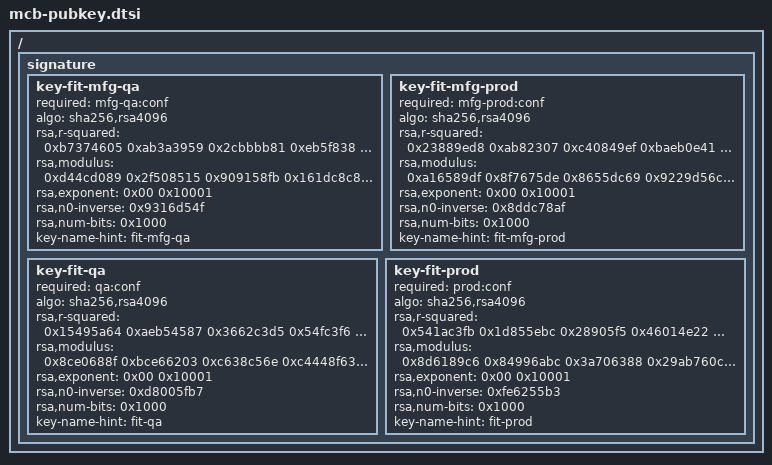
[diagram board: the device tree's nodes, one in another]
/*
 * This is a Device Tree representation of the public keys that will
 * be used for FIT image verification.
 *
 * The procedure to generate this file from production keys in AWS CloudHSM is
 * avaliable here:
 * https://github.com/ChargePoint/emb-platform/blob/master/os/buildroot/package/emb-sbsigner/README.md
 */

/ {
	signature {

		key-fit-mfg-qa {
			required = "mfg-qa:conf";
			algo = "sha256,rsa4096";
			rsa,r-squared = < 0xb7374605 0xab3a3959 0x2cbbbb81 0xeb5f838 0x4bb5653e 0x18479cb6 0x23d0299f 0x4a56102b 0x6a9e6eba 0xea80ffea 0x2d5070d3 0x5fa6fe54 0x507ae7ad 0x3aa41cde 0x8d3a9ec5 0x6e343eb9 0x74f7d490 0xa2283000 0xf7cd028e 0xb794887d 0xb8b51228 0x1b12023f 0xc6bfa648 0x9c294dad 0xa33be023 0xcb2aaed3 0x1f97247 0x3438b15e 0x2d983a2c 0x526e42d4 0x14bdcc2c 0x8b406381 0x181fa997 0xc7b0e240 0x1bff5a28 0xa4deac87 0xe7b06f11 0x18ae0268 0x1ac54201 0xb32e41c5 0xcaaf0143 0x4a75bc9d 0xee715a30 0xf1fad5bf 0xf6d3fed2 0xff18a269 0xe4a86270 0x73f8cc03 0x4ee7aa5b 0x70a17104 0x7c1811c4 0xee1278aa 0xa22c16a2 0x71caebb 0x80285c83 0x7ce4504e 0xffccbbb3 0xe9a33e58 0xc27dc984 0x77eb382e 0x5c9610b7 0xf753acd 0x139deb12 0x29228785 0x30664657 0x906d7fe7 0x4f19ae47 0x1ca5cc12 0x1e208295 0x3cbcb9e2 0x86f11f98 0xe92e1594 0x96698255 0x2dac40fb 0x45a97135 0xe507ae94 0xe5ec1da7 0xeec2c49e 0x47b8ca65 0xe560ae12 0xe63d7650 0x6ab8a9ba 0x5ea440ea 0x78b3335a 0xa39d192 0x9a9b6327 0x4a6e2e52 0x795c4ce6 0x4fa55ec0 0x2efc6b5 0xea68e5df 0x72b4c17e 0x83c40126 0xf93f7625 0xcbe4b2d0 0x5a214246 0x247450e0 0x138197f 0xeee2b322 0x7202af22 0xb77ba753 0x89540957 0x70e0ddce 0xfe02437e 0x11fc7334 0x22f77f8f 0x6d27c05a 0x4e550443 0x1a2a149 0x2f821663 0x2af2fe25 0x1b2d7264 0x1fe17305 0x4994d1d1 0x62718b90 0x417c20e9 0x78d5d38 0xb53ed94b 0x2ba941a5 0x2c01126f 0x75b04cd2 0x4f067000 0x5a27da80 0xd6bb6afa 0x5bad1089 0x26c62004 0xce938f8c 0x9a3a44d >;
			rsa,modulus = < 0xd44cd089 0x2f508515 0x909158fb 0x161dc8c8 0xe42be8e1 0xcb358437 0x4e59c9f3 0xf8543b68 0xc46063a9 0x6f4085a0 0x5c45fb 0x5e05d982 0x8d24a2e 0x9d522364 0x4a76566c 0xd574c659 0xd990678d 0xcb94a136 0x37066b65 0xb46c07b8 0xbdbc9a7 0xf831d136 0x66bcb0b7 0x35665019 0x3116a2c0 0x999b0bd7 0x13ee6e22 0xeb82173b 0x9695264b 0x1ac913ea 0xcfa27c0f 0x995e0480 0x9ed6e5de 0x1e25eee1 0xb8ecfdc9 0x2c061949 0x1115d029 0xa053b099 0xeac0dfb1 0x63f5b33a 0xe37b9b6e 0x3e53d994 0x320fa7bb 0xb23a85cf 0xc55e692f 0x35785e7a 0x92707329 0x49c91f20 0x54d40d21 0xe9045889 0x379cb8e0 0x964ab616 0x4aa06508 0x413e7496 0x274c1c37 0xd146603f 0x783b1f7b 0x59f88fbc 0xcb06b705 0x54998bc1 0x21959b1c 0x51fc777f 0x3676f7dd 0xa80ef651 0xa248c11a 0xb2ba3198 0x14d7cd4d 0x3459ba41 0xcf7643e3 0x6b305db1 0xa4e40595 0x435a2b1f 0x4ea42f 0x1bca30b4 0x813f50e7 0xd231b19a 0x1037cb45 0x5b39e4ff 0x6271152 0x6e49a21c 0xc9a2d516 0xabce00a0 0x9ed09986 0x78c48125 0x39a0b13b 0xdf81ea38 0xa93f87ad 0x28a32d76 0x9dc4c79a 0x664f6a02 0x8c14d961 0x22da3e23 0xea7e044a 0xdd5b4fb8 0x227c1c43 0x3c5a99db 0xf2512163 0x11c90ebc 0xee7ac908 0x14a3d1d1 0x5646e484 0x66946c43 0x7d4f9198 0x2c8ed56f 0x64eb80e4 0x661880bf 0xc557e3b 0x95055d31 0xf9f3acba 0x9b426dcb 0xf742efe0 0x14ec5d46 0x6ab85040 0xadedf8f6 0x2cdb9f45 0xe236a2e9 0xe5536366 0xef085fd6 0x639d39b3 0x9a04b42c 0x7037314b 0xbd386ed2 0x34661843 0x9109be89 0x4f5801e6 0x766b4a89 0x55e7901 0xaf74de51 >;
			rsa,exponent = < 0x00 0x10001 >;
			rsa,n0-inverse = < 0x9316d54f >;
			rsa,num-bits = < 0x1000 >;
			key-name-hint = "fit-mfg-qa";
		};

		key-fit-mfg-prod {
			required = "mfg-prod:conf";
			algo = "sha256,rsa4096";
			rsa,r-squared = < 0x23889ed8 0xab82307 0xc40849ef 0xbaeb0e41 0x5dbce411 0x74c7f91e 0x77b7d250 0x2e4b63bc 0x32fe6bfa 0xf70082f 0x407437f2 0x3c21524a 0xc77dce31 0x8b02f80 0x5bf54f03 0x32970f8d 0x406422d7 0x884ed230 0x156e777b 0xdd82352f 0xcb285f9e 0xd79a7adb 0xd1da32df 0x5fa5f627 0xa7da35ba 0x9ac520b 0x6822dafe 0x365d2c6 0xf539c6b2 0x37f26ad2 0x9fc90bb1 0xe3e40369 0x2ed8f887 0xf39e783b 0xf298713c 0x49af365d 0x9a6db052 0x7ff973e1 0x8af9ae8a 0x276f08bd 0xfe29b3e 0x5d5e0729 0x40d96899 0x108e84e7 0xff19b189 0x95e89e67 0x6e1be4a0 0xc99260f3 0x8faedcd2 0xb6ff8db2 0x89cf4abc 0x8daeeec3 0x6c6b8b79 0x5c0ef38a 0xd371fb2c 0xa55f5412 0x5e5313ba 0xdc2a9a44 0xacef10a4 0x7d66655 0xfcb00906 0x711cf3af 0xb07328cd 0xed39b2e5 0x51794016 0x2893d500 0xa44a737f 0x69449642 0x25090b92 0x42ca92ee 0xb79cc389 0x6fb5ca7d 0x8e0d02b7 0x89e007f6 0x7caef7bd 0xc3a01188 0xa2820f5f 0x28d21bfa 0x540c2f50 0x547d3c59 0x967f0f4 0x9861b9fb 0x476ef541 0x9a264d31 0x3801bd6f 0xb9108d54 0xfd86416b 0x69d4261f 0x54891503 0xa12a54c1 0x98729a45 0xabd9f4ee 0x1f111d9f 0xa7001566 0x8b6a6e98 0x90a72ff3 0xcc1cd871 0x18f5a633 0x5ed5785 0xc5422565 0xdc1ae61d 0x2716a8fc 0xc5a3c283 0x465de09d 0x1e4450ff 0x850fbb66 0xe50057ec 0x47f7badc 0xf04405de 0xbc4cb23d 0xb8707688 0xf25338f2 0x405191dc 0xfa14c36e 0x6a1d519 0x124a520f 0xf7f06f55 0xb01fa935 0xdb514996 0x858afb70 0xaf49a6b7 0x6d62297c 0xb20e0e9b 0xf4218951 0x68798f47 0x65fd9889 0x2340af6f 0xc3dceb81 >;
			rsa,modulus = < 0xa16589df 0x8f7675de 0x8655dc69 0x9229d56c 0x8a614f7f 0xffe127f7 0x75438a85 0xee258e51 0xd449939a 0xc0a0f602 0xbbad5bb1 0x7b47e749 0x9c3f47c8 0x89678af2 0x41e5efae 0x42e2db43 0x1be13850 0x8246ebec 0x22b66a6f 0xfcac6fec 0x1a5f11b5 0x6f633b0 0xf56f051 0xbb520065 0x1ec453f0 0xa6c1e801 0x52bcc085 0xec109193 0xd6ce62d 0x3ec8fee9 0xba56bc86 0x4b778c41 0x60f2c0ca 0xa8b23783 0x72f3a56a 0x38c1566 0xddc39fd4 0x4bd4c6c3 0x94b5cdc2 0x236cb502 0xd3ca3845 0xbee455a7 0x1633852 0x20d76a2e 0xe5ce52aa 0x8c9834d6 0xc5d8278e 0x5377fc70 0x59eb07a1 0x9fe3d1c7 0x336a1e85 0x96fdcde 0x44941786 0xf60e9dd3 0x6d96b390 0x9ec595d6 0xfbf44a8e 0xc7dcd3ed 0x559463b 0x3bd8a7e1 0xd23abd2f 0x13c9a548 0xf110d98f 0x83752ef2 0x94d9117c 0xd9fa020a 0x76f6afc3 0x37f64566 0x94f5ba99 0x78bcdcc 0xdfd8f576 0xb9adf23b 0x76faaa77 0x70848503 0x78d62571 0x55425e19 0xef4a4f29 0x993530ab 0xe1706317 0x4159a085 0x53f7f591 0x81f2317b 0x1d20901e 0x5b639e7 0x31c8c4b7 0xfb186846 0x95cd877a 0x12f7096e 0x6b9ab6d3 0x3fe1367a 0xe8ef00ac 0x3bc6b19e 0x4a518042 0xcbf0e16a 0x46fd3e3d 0x5b17d999 0xdc0890e8 0x2486f3fc 0x867a00d6 0x353a92de 0xab4f5696 0x8b3bd97a 0x4f6f7cba 0x822d429d 0xae384944 0x930b91cd 0x4161dabe 0xa87b3652 0xd6c4a2a3 0xe5e3c0c1 0x558f3a42 0x305e703a 0x9cc9846b 0x723a19c7 0xcf91bdae 0x40ac9e31 0x9ff184de 0xaffd7eac 0xc16fceff 0x1a24fc06 0x7e12cfe5 0xbbf04dcc 0xcb3a3985 0xc8aff89c 0x1607f932 0xf345570f 0xa438fbfd 0xed9e21b1 >;
			rsa,exponent = < 0x00 0x10001 >;
			rsa,n0-inverse = < 0x8ddc78af >;
			rsa,num-bits = < 0x1000 >;
			key-name-hint = "fit-mfg-prod";
		};

		key-fit-qa {
			required = "qa:conf";
			algo = "sha256,rsa4096";
			rsa,r-squared = < 0x15495a64 0xaeb54587 0x3662c3d5 0x54fc3f6 0x148be21f 0xc77f2c2c 0x6d8e81f 0x89b37025 0x2247f557 0x1f0d5d9a 0xc617432e 0x8efe7e70 0xece6f56b 0x40b6c4df 0x78ff547e 0xbddc2bbf 0x26b0cf28 0x1986fd0 0x7b4165cf 0xf5e9aee0 0xefe3be79 0x3760312c 0xc0814d32 0x6d580731 0xab81aa0 0xedd28d43 0x176dface 0xe9d78622 0xa58c39fd 0x5d8052af 0x2dffe133 0x62ff2526 0xf6c202ac 0x191c65ef 0x1f02d878 0xea8f21a7 0x777b7b6c 0x76c69d6f 0x9b57c244 0xc76507ea 0xfae1aa20 0xa1e5d79 0xed5a5f20 0x5d0e58dd 0x3c7146a2 0x26f80576 0x3d7d975a 0xcd31a31b 0xc45f7234 0xb9df8bc9 0x2d899042 0x2728f8e9 0x25ba4248 0xbeca2dd7 0x3ee1bcee 0x1d6f7e29 0x69fa348b 0x565d26fa 0xb8ae8bab 0x7482c87d 0x8bb85bd3 0xfb1a5f72 0x601c35f8 0xf4ad5722 0xe3cbb695 0x1f0d7f60 0x9f3adedc 0xb20255df 0x1c1d3a13 0x4d0d38fb 0x326de1ca 0x99c9a4ea 0x7397a66 0x6eeb03f7 0x97e0aa9a 0x4f64fcda 0x91d8f5d7 0x32e8dd57 0x7ee8b284 0x2434fb09 0xe809bb86 0xa186e5b1 0x5211d085 0xed1712fb 0x8712bdcc 0x6ae49963 0x4d418f43 0xf93f4e6a 0x539b83c2 0x9b52efa1 0x1f51cdbe 0xb99ebd98 0x74ea447a 0x697e4795 0x182e31ff 0x3bf831a3 0x923b6bd1 0xd0dc6977 0xd3eaa8c7 0x4091d3d5 0x46103345 0x19e55d0d 0x21af930c 0x9d07b2bc 0xe433ca38 0x904ba11a 0x47ee12b0 0xf2b99a67 0xb14179ef 0x5ae422e4 0xa2880a00 0x315c555d 0xbec59dbc 0x5d40ccab 0xbd1b6a5d 0x3932dc1a 0x3a317319 0x4b75a003 0x4d545e17 0xc66115e3 0x9fa54c81 0x9e29fd68 0xfc7d46ca 0x2b8b2690 0xc61bb848 0x131c8536 0xb298957e 0xad17309 >;
			rsa,modulus = < 0x8ce0688f 0xbce66203 0xc638c56e 0xc4448f63 0x2f6b0147 0x4953876b 0x5c5cab1 0xc35e05ee 0x5c3949b8 0x40107924 0x5c2405a3 0x7e2c931e 0x4abc4ea8 0x775d5753 0xe7c2c879 0x7ac35ef3 0x238bf13d 0xe274e253 0x553da593 0xa33f8714 0xab0a4606 0xc981eae9 0x38a41ef7 0xe6042ab0 0xeee19070 0xc549c674 0xd6808ce1 0xbc5dc53a 0x589ae834 0xae7c304a 0x3cb08586 0x2d858969 0xa9a21242 0x59ecc6f8 0x85d6f99e 0xcf998f3d 0x1f35e786 0xc22168d 0x135b897d 0x59a53d02 0xc03a0a8 0xe497eff0 0xd90016c3 0xf382d171 0x85342f7d 0x38680118 0x5b872bf7 0x865663e2 0xc8d2ea9b 0xe7515c1 0x2a767cc3 0x982a443d 0x2831a69d 0x75f108bf 0x7ca4e81 0x38387ae9 0xa12aaca7 0x93bd7ed4 0x17adf67f 0x8a83d4b5 0xe7a3f0d2 0xcd1baaf6 0x7fa7ba6b 0x7326b0eb 0x505092bd 0xe9aaa72d 0x8c101d1 0x70010510 0xff18e6f0 0xcdb3ba4e 0xff43ac97 0x1cc7d59e 0x319e9277 0xe9ba958a 0x26b03a72 0x5672ba0d 0xf393a90b 0x223ed99e 0x7e39ae2f 0x1e77c653 0x79d27c3f 0x79af9413 0x5ac9000d 0x65d99b47 0x63ed0d6 0xec5cc979 0x744c722d 0xf3f831a6 0x67e71a2d 0xd9f893e2 0xb12b297d 0x7e6ab844 0xce77e64b 0xeef897d3 0x526d6796 0x84f02476 0x483b3e43 0xc0867641 0x3b2b5573 0xf20e4b4d 0xa2f6d84f 0xf1f27d64 0x378b4c20 0x5a1669ee 0x25672015 0x652d61fc 0xb5d1bdd2 0x5d99f4b0 0x87559b51 0x45762787 0x50b08a99 0x498c6075 0xeb54fc91 0x32f24a0c 0x3c3e786a 0x61ab034d 0x161d4b47 0xa3a9d9dc 0x5653dffc 0xc243fa25 0x76737d02 0xbbffbcc8 0xe1c96e2d 0x9b28fefc 0x8dfb33fa 0x951099a9 0x7a43ab7e 0xad7651f9 >;
			rsa,exponent = < 0x00 0x10001 >;
			rsa,n0-inverse = < 0xd8005fb7 >;
			rsa,num-bits = < 0x1000 >;
			key-name-hint = "fit-qa";
		};

		key-fit-prod {
			required = "prod:conf";
			algo = "sha256,rsa4096";
			rsa,r-squared = < 0x541ac3fb 0x1d855ebc 0x28905f5 0x46014e22 0x3c264f81 0x28bdcb03 0xb99b7c48 0x2df88eec 0xe05949df 0x32275703 0x56696f36 0x363e2c9a 0xba71c108 0x35688c40 0x4ddf3cdf 0x2c5195e3 0x597ebcc9 0xcc9ed720 0xbc126834 0xca9ec611 0x3814090 0x5692a927 0x236f600e 0x200897dc 0xb7fff46a 0xd9a29448 0xcc057155 0x279a2516 0x2f2cd853 0xdd89ef89 0x747fef67 0xe8f15611 0xf4caa737 0xfe4f2552 0x15660b72 0x30f66fd5 0xac766c5f 0x6b564577 0xc3372e5 0x505e6526 0x7ba11 0xb1e393c3 0xb86dfb30 0x507da0af 0x624dcecc 0x70d55054 0x339ea089 0x5c8748fd 0x13c8a2b7 0xb92f7a20 0xec36928 0x351bbc06 0xee407cc0 0xa95afda8 0x54788b3 0x3c739b0b 0x389f7fa6 0x58b49ae5 0xda15056d 0x60ddf380 0x5fca9c07 0xb9ad51f1 0x66fbcc9a 0x7ac88404 0x3e162e68 0x7a37a927 0xf03b1701 0x9d1c12ff 0x52102625 0x57d8c2f0 0x206d0d46 0xe8827ae0 0xc9e582ba 0x8555d909 0xcc83e4cb 0xc075e91e 0xf421846f 0x7738786b 0xc80a430f 0x2c42385d 0x562548d9 0xe7e50c76 0xe7c22d25 0xe7602b6f 0x6061bb2b 0xfd3cd9ea 0x57c7d75d 0x4a075eeb 0x32d2d420 0x6ccb48bc 0x370efefa 0x3e9ce749 0x5d7bb6d8 0xdf1d428e 0xe81e546b 0xf95fa7c9 0x962c3e36 0xa250b041 0x93b50007 0x9a18aa0d 0x7862b6a7 0x2d52eee4 0x3d208dd8 0x4cdb338a 0x4bcfea6 0x411f01fe 0x716408b4 0x9cf1e898 0x240b17c 0x5ead2ab8 0x894b063a 0x6fdb88ba 0x809d014 0xf2919389 0xf0a9857b 0x4cdd9e98 0xd6094282 0x80277c4a 0xbb3dd26d 0xaee40751 0x3a4915bc 0x6bb56d99 0x97271fb7 0x243d1f05 0x92f517b6 0xb4ad78f9 0x70532991 0xa1b68493 >;
			rsa,modulus = < 0x8d6189c6 0x84996abc 0x3a706388 0x29ab760c 0x2d10619d 0xd145915f 0x3e29d6d8 0x2741f771 0x68bd068a 0x67821370 0x7d0e444e 0xa82c69c9 0x998dd53e 0x580ee5a9 0xc540deb0 0xcf5329a2 0x4fd2138d 0x40b2e4a2 0x563ccc91 0x3fab5b42 0xe8f5ad43 0xcc8a5ff8 0x7d02a8f8 0x11554ee5 0x3ac89fa3 0x83fa10fe 0x2b14b47f 0x9d3a088f 0xbda98d57 0x5ff71fc 0xbb1d397a 0xa71eb432 0xa1dba8e3 0x67810abc 0xd8419988 0x78e96766 0xc27eff17 0x1502260a 0xaf79ce6a 0x4664ebab 0x6c7a0434 0x11d31c77 0x7adbc12 0xca720822 0xfdc072dd 0x71106fe 0x58b2e5a3 0xbada3b4d 0x500b29f2 0x126c5a7a 0x4980b63a 0xb315482c 0x3c41bdb0 0xafdba3c 0xaba384d2 0x55622a4d 0x2b9c8bb4 0xb04fdae 0xe8ae216 0x5b99e310 0xdaf118ec 0x967b9f47 0x30d1d432 0x2eebe899 0x798df469 0xbf8394bb 0x5e924562 0xcf220806 0xa2caa708 0x8d22c6fb 0x67fa7f79 0xe2e31f61 0xc6f572a1 0x870b1f5 0x3383033b 0x9f1d76f6 0x88321298 0xb0aad1c7 0xbf98d555 0x17632020 0x7a75a08 0x3d4dff6b 0x323ceeb6 0x5fbb9587 0x70ab7c1d 0xea1e20a7 0x4fb6b788 0x5d1e5146 0xca3f44c8 0xdb10efb9 0x3856905 0x70d3ebba 0x317d9a98 0x9503b0fa 0x3ec3c811 0x4712d91c 0x5235407b 0xd5d075a 0x454c22cc 0x1c302767 0x8ed8bb61 0x6a51089c 0x58bd69b4 0x4e2cb04c 0xab2acdce 0xe6e87cbf 0xac23051b 0xbfe133d1 0xa2ec0898 0xa17b9e61 0x62b5043a 0x82adbc48 0xa4706bd 0x3319d2bd 0x559bbb50 0x8e1ba6fd 0xb8441c67 0xb1adb8f 0x7eb7e3aa 0x96e51c1d 0xf60374ab 0x65e116be 0xd1cd4476 0x74affb5f 0x22be7056 0x59a163b1 0x17ff38ec 0x29679e85 >;
			rsa,exponent = < 0x00 0x10001 >;
			rsa,n0-inverse = < 0xfe6255b3 >;
			rsa,num-bits = < 0x1000 >;
			key-name-hint = "fit-prod";
		};
	};
};

